# ATmega16U4 device description
Architecture: AVR8; Family: megaAVR
Registers are 8-bit, access not given, no defined reset value unless marked. A register's access mark holds for its fields unless they carry their own. Offsets are from the block's base; [hi:lo] are bit positions.

## LOCKBIT — Lockbits
Instances: LOCKBIT 0 in lockbits
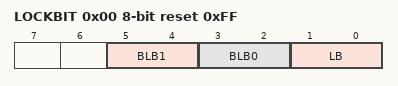
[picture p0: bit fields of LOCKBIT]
0x00 LOCKBIT reset 0xFF
  [5:4] BLB1 — Boot Loader Protection Mode
    0=LPM_SPM_DISABLE (LPM and SPM prohibited in Boot Section); 1=LPM_DISABLE (LPM prohibited in Boot Section); 2=SPM_DISABLE (SPM prohibited in Boot Section); 3=NO_LOCK (No lock on SPM and LPM in Boot Section)
  [3:2] BLB0 — Boot Loader Protection Mode
    0=LPM_SPM_DISABLE (LPM and SPM prohibited in Application Section); 1=LPM_DISABLE (LPM prohibited in Application Section); 2=SPM_DISABLE (SPM prohibited in Application Section); 3=NO_LOCK (No lock on SPM and LPM in Application Section)
  [1:0] LB — Memory Lock
    0=PROG_VER_DISABLED (Further programming and verification disabled); 2=PROG_DISABLED (Further programming disabled); 3=NO_LOCK (No memory lock features enabled)

## WDT — Watchdog Timer
Instances: WDT 0x00
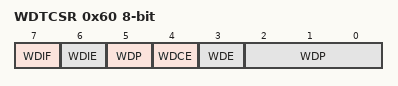
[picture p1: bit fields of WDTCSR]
0x60 WDTCSR — Watchdog Timer Control Register
  [7] WDIF — Watchdog Timeout Interrupt Flag
  [6] WDIE — Watchdog Timeout Interrupt Enable
  [4] WDCE — Watchdog Change Enable
  [3] WDE — Watch Dog Enable
  [5,2:0] WDP — Watchdog Timer Prescaler Bits
    0=OSCILLATOR_CYCLES_2K; 1=OSCILLATOR_CYCLES_4K; 2=OSCILLATOR_CYCLES_8K; 3=OSCILLATOR_CYCLES_16K; 4=OSCILLATOR_CYCLES_32K; 5=OSCILLATOR_CYCLES_64K; 6=OSCILLATOR_CYCLES_128K; 7=OSCILLATOR_CYCLES_256K; 8=OSCILLATOR_CYCLES_512K; 9=OSCILLATOR_CYCLES_1024K

## PORTD — I/O Port
Instances: PORTD 0x00
0x29 PIND — Port D Input Pins
0x2A DDRD — Port D Data Direction Register
0x2B PORTD — Port D Data Register

## PORTB — I/O Port
Instances: PORTB 0x00
0x23 PINB — Port B Input Pins
0x24 DDRB — Port B Data Direction Register
0x25 PORTB — Port B Data Register

## PORTC — I/O Port
Instances: PORTC 0x00
0x26 PINC bits used 7:6 — Port C Input Pins
0x27 DDRC bits used 7:6 — Port C Data Direction Register
0x28 PORTC bits used 7:6 — Port C Data Register

## PORTE — I/O Port
Instances: PORTE 0x00
0x2C PINE bits used 6,2 — Input Pins, Port E
0x2D DDRE bits used 6,2 — Data Direction Register, Port E
0x2E PORTE bits used 6,2 — Data Register, Port E

## PORTF — I/O Port
Instances: PORTF 0x00
0x2F PINF bits used 7:4,1:0 — Input Pins, Port F
0x30 DDRF bits used 7:4,1:0 — Data Direction Register, Port F
0x31 PORTF bits used 7:4,1:0 — Data Register, Port F

## SPI — Serial Peripheral Interface
Instances: SPI 0x00
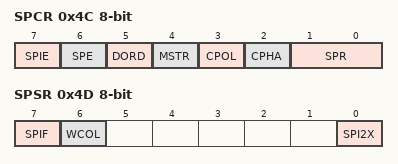
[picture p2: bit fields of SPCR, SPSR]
0x4C SPCR — SPI Control Register
  [7] SPIE — SPI Interrupt Enable
  [6] SPE — SPI Enable
  [5] DORD — Data Order
  [4] MSTR — Master/Slave Select
  [3] CPOL — Clock polarity
  [2] CPHA — Clock Phase
  [1:0] SPR — SPI Clock Rate Selects
    0=FOSC_4; 1=FOSC_16; 2=FOSC_64; 3=FOSC_128; 4=FOSC_2; 5=FOSC_8; 6=FOSC_32; 7=FOSC_64
0x4D SPSR — SPI Status Register
  [7] SPIF — SPI Interrupt Flag
  [6] WCOL — Write Collision Flag
  [0] SPI2X — Double SPI Speed Bit
0x4E SPDR — SPI Data Register
  [7:0] SPDR — SPI Data bits

## USART1 — USART
Instances: USART1 0x00
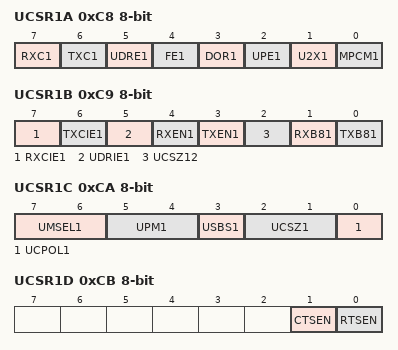
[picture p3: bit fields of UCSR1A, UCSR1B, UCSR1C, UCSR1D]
0xC8 UCSR1A — USART Control and Status Register A
  [7] RXC1 — USART Receive Complete
  [6] TXC1 — USART Transmit Complete
  [5] UDRE1 — USART Data Register Empty
  [4] FE1 — Framing Error
  [3] DOR1 — Data overRun
  [2] UPE1 — Parity Error
  [1] U2X1 — Double the USART transmission speed
  [0] MPCM1 — Multi-processor Communication Mode
0xC9 UCSR1B — USART Control and Status Register B
  [7] RXCIE1 — RX Complete Interrupt Enable
  [6] TXCIE1 — TX Complete Interrupt Enable
  [5] UDRIE1 — USART Data register Empty Interrupt Enable
  [4] RXEN1 — Receiver Enable
  [3] TXEN1 — Transmitter Enable
  [2] UCSZ12 — Character Size
  [1] RXB81 — Receive Data Bit 8
  [0] TXB81 — Transmit Data Bit 8
0xCA UCSR1C — USART Control and Status Register C
  [7:6] UMSEL1 — USART Mode Select
    0=ASYNCHRONOUS_USART; 1=SYNCHRONOUS_USART; 3=MASTER_SPI
  [5:4] UPM1 — Parity Mode Bits
    0=DISABLED; 2=ENABLED_EVEN_PARITY; 3=ENABLED_ODD_PARITY
  [3] USBS1 — Stop Bit Select
    0=1_BIT; 1=2_BIT
  [2:1] UCSZ1 — Character Size
  [0] UCPOL1 — Clock Polarity
0xCB UCSR1D — USART Control and Status Register D
  [1] CTSEN — CTS Enable
  [0] RTSEN — RTS Enable
0xCC UBRR1 16-bit bits used 11:0 — USART Baud Rate Register Bytes
0xCE UDR1 — USART I/O Data Register
  [7:0] UDR1 — USART I/O Data bits
